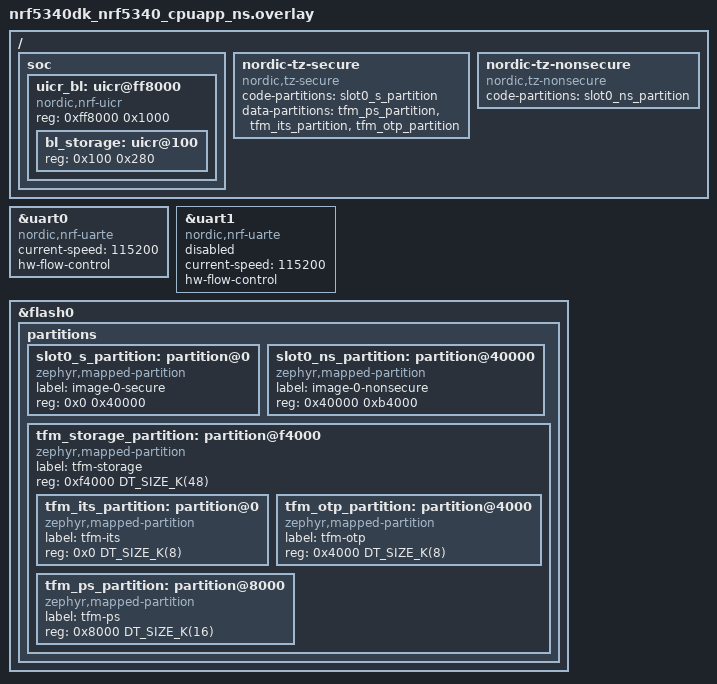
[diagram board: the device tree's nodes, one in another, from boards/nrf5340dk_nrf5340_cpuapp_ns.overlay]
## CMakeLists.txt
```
#
# Copyright (c) 2022 Nordic Semiconductor ASA
#
# SPDX-License-Identifier: LicenseRef-Nordic-5-Clause
#

cmake_minimum_required(VERSION 3.20.0)

if(${CMAKE_MAJOR_VERSION} EQUAL "3" AND ${CMAKE_MINOR_VERSION} EQUAL "25")
message(FATAL_ERROR "CMake versions 3.25.x are not compatible wth the PSA architecture tests.\n"
                    "Use an earlier (<= 3.24.x) or later (>= 3.26.x) version of CMake.")
endif()

find_package(Zephyr REQUIRED HINTS $ENV{ZEPHYR_BASE})

project(tfm_psa_test)

target_sources(app PRIVATE src/main.c)

get_target_property(TFM_BINARY_DIR           tfm TFM_BINARY_DIR)
get_target_property(TFM_NS_BIN_FILE          tfm TFM_NS_BIN_FILE)
get_target_property(TFM_NS_HEX_FILE          tfm TFM_NS_HEX_FILE)
get_target_property(TFM_NS_SIGNED_BIN_FILE   tfm TFM_NS_SIGNED_BIN_FILE)

get_target_property(TFM_TOOLCHAIN_PATH       tfm TFM_TOOLCHAIN_PATH)
get_target_property(TFM_TOOLCHAIN_PREFIX     tfm TFM_TOOLCHAIN_PREFIX)
get_target_property(TFM_TOOLCHAIN_NS_FILE    tfm TFM_TOOLCHAIN_NS_FILE)

set(TFM_TEST_REPO_PATH ${ZEPHYR_TRUSTED_FIRMWARE_M_MODULE_DIR}/../tf-m-tests)
set(TFM_PSA_ARCHTEST_REPO_PATH ${ZEPHYR_TRUSTED_FIRMWARE_M_MODULE_DIR}/../psa-arch-tests)

set(TFM_TEST_DIR         "${TFM_TEST_REPO_PATH}/tests_psa_arch/spe/partitions")
set(PSA_ARCH_TESTS_CONFIG_FILE "${TFM_TEST_REPO_PATH}/tests_psa_arch/spe/config/config_test_psa_api.cmake")

if(CONFIG_TFM_PSA_TEST_CRYPTO)
  set(TFM_PSA_TEST_SUITE CRYPTO)
elseif(CONFIG_TFM_PSA_TEST_PROTECTED_STORAGE)
  set(TFM_PSA_TEST_SUITE PROTECTED_STORAGE)
elseif(CONFIG_TFM_PSA_TEST_INTERNAL_TRUSTED_STORAGE)
  set(TFM_PSA_TEST_SUITE INTERNAL_TRUSTED_STORAGE)
elseif(CONFIG_TFM_PSA_TEST_STORAGE)
  set(TFM_PSA_TEST_SUITE STORAGE)
elseif(CONFIG_TFM_PSA_TEST_INITIAL_ATTESTATION)
  set(TFM_PSA_TEST_SUITE INITIAL_ATTESTATION)
endif()

if(NOT DEFINED TFM_PSA_TEST_SUITE)
  message(FATAL_ERROR "Please define witch test suite to run:
    CONFIG_TFM_PSA_TEST_CRYPTO
    CONFIG_TFM_PSA_TEST_PROTECTED_STORAGE
    CONFIG_TFM_PSA_TEST_INTERNAL_TRUSTED_STORAGE
    CONFIG_TFM_PSA_TEST_STORAGE
    CONFIG_TFM_PSA_TEST_INITIAL_ATTESTATION")
endif()
set(TEST_PSA_API "${TFM_PSA_TEST_SUITE}")

set_property(TARGET zephyr_property_target
             APPEND PROPERTY TFM_CMAKE_OPTIONS
             -DCONFIG_TFM_TEST_DIR=${TFM_TEST_DIR}
             -DTFM_PROFILE=profile_large
)

set_property(TARGET zephyr_property_target
             APPEND PROPERTY TFM_CMAKE_OPTIONS
             -DPSA_ARCH_TESTS_PATH=${TFM_PSA_ARCHTEST_REPO_PATH}
)

set_property(TARGET zephyr_property_target
             APPEND PROPERTY TFM_CMAKE_OPTIONS
             -DCONFIG_PSA_ARCH_TESTS_CONFIG_FILE=${PSA_ARCH_TESTS_CONFIG_FILE}
)

set_property(TARGET zephyr_property_target
             APPEND PROPERTY TFM_CMAKE_OPTIONS
             -DTEST_PSA_API=${TEST_PSA_API}
)

set(INSTALL_INTERFACE_INC_DIR ${CMAKE_BINARY_DIR}/tfm/api_ns/interface/include)

file(
  COPY
    ${ZEPHYR_OBERON_PSA_CRYPTO_MODULE_DIR}/include/psa/crypto_compat.h
    ${ZEPHYR_OBERON_PSA_CRYPTO_MODULE_DIR}/include/psa/crypto_driver_common.h
    ${ZEPHYR_OBERON_PSA_CRYPTO_MODULE_DIR}/include/psa/crypto_extra.h
    ${ZEPHYR_OBERON_PSA_CRYPTO_MODULE_DIR}/include/psa/crypto_platform.h
    ${ZEPHYR_OBERON_PSA_CRYPTO_MODULE_DIR}/include/psa/crypto_sizes.h
    ${ZEPHYR_OBERON_PSA_CRYPTO_MODULE_DIR}/include/psa/crypto_struct.h
    ${ZEPHYR_OBERON_PSA_CRYPTO_MODULE_DIR}/include/psa/crypto_types.h
    ${ZEPHYR_OBERON_PSA_CRYPTO_MODULE_DIR}/include/psa/crypto_values.h
    ${ZEPHYR_OBERON_PSA_CRYPTO_MODULE_DIR}/include/psa/crypto.h
    ${NRF_SECURITY_DIR}/include/psa/crypto_driver_contexts_key_derivation.h
    ${NRF_SECURITY_DIR}/include/psa/crypto_driver_contexts_primitives.h
    ${NRF_SECURITY_DIR}/include/psa/crypto_driver_contexts_composites.h
  DESTINATION
    ${INSTALL_INTERFACE_INC_DIR}/psa
)

# The PSA arch test non-secure app is built by the TF-M build system instead of
# Zephyr, so it takes its console UART from TF-M's NS_DRIVER_STDIO (platform
# target_cfg.h) rather than from Kconfig. NS_DRIVER_STDIO is derived from
# NRF_SECURE_UART_INSTANCE, which modules/trusted-firmware-m/CMakeLists.txt only
# passes to the secure build, so pass it to the non-secure build here as well.
foreach(uart_instance 0 1 00 20 21 22 30)
  if(CONFIG_TFM_SECURE_UART${uart_instance})
    set(tfm_ns_c_flags -DNRF_SECURE_UART_INSTANCE=${uart_instance})
  endif()
endforeach()

include(ExternalProject)

if(CONFIG_DEBUG_OPTIMIZATIONS)
  set(tfm_ns_CMAKE_BUILD_TYPE Debug)
else()
  set(tfm_ns_CMAKE_BUILD_TYPE RelWithDebInfo)
endif()

ExternalProject_Add(tfm_psa_arch_test_app
    SOURCE_DIR ${TFM_TEST_REPO_PATH}/tests_psa_arch
    BINARY_DIR ${PROJECT_BINARY_DIR}/tfm_ns
    CONFIGURE_COMMAND
        ${CMAKE_COMMAND}
                -G ${CMAKE_GENERATOR}
                -S ${TFM_TEST_REPO_PATH}/tests_psa_arch
                -B ${PROJECT_BINARY_DIR}/tfm_ns
                -DCONFIG_SPE_PATH=${TFM_BINARY_DIR}/api_ns
                -DTFM_TOOLCHAIN_FILE=cmake/${TFM_TOOLCHAIN_NS_FILE}
                -DCROSS_COMPILE=${TFM_TOOLCHAIN_PATH}/${TFM_TOOLCHAIN_PREFIX}
                -DPSA_TOOLCHAIN_FILE=${TFM_BINARY_DIR}/api_ns/cmake/${TFM_TOOLCHAIN_NS_FILE}
                -DQCBOR_PATH${QCBOR_PATH_TYPE}=${CONFIG_TFM_QCBOR_PATH}
                -DT_COSE_PATH=${CONFIG_TFM_T_COSE_PATH}
                -DCMAKE_BUILD_TYPE=${tfm_ns_CMAKE_BUILD_TYPE}
                -DTEST_PSA_API=${TEST_PSA_API}
                -DZEPHYR_NRF_MODULE_DIR=${ZEPHYR_NRF_MODULE_DIR}
                -DTFM_BOARDS_NRF_DIR=${TFM_BOARDS_NRF_DIR}
                -DNRF_CONFIG_CPU_FREQ_MHZ=${CONFIG_TFM_CPU_FREQ_MHZ}
                -DCMAKE_C_FLAGS=${tfm_ns_c_flags}
    BUILD_COMMAND ${CMAKE_COMMAND} --build .
    INSTALL_COMMAND ""
    BUILD_ALWAYS True
    USES_TERMINAL_BUILD True
    WORKING_DIRECTORY ${PROJECT_BINARY_DIR}/tfm_ns
    DEPENDS tfm
    BUILD_BYPRODUCTS
        ${TFM_NS_HEX_FILE}
        ${TFM_NS_BIN_FILE}
        ${TFM_NS_SIGNED_BIN_FILE}
)

add_dependencies(app tfm_psa_arch_test_app)
```

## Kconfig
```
#
# Copyright (c) 2026 Nordic Semiconductor ASA
#
# SPDX-License-Identifier: LicenseRef-Nordic-5-Clause
#

# Applies only to the targets with the CC3XX identity key backend.
configdefault IDENTITY_KEY_TFM
	default y

source "Kconfig.zephyr"
```

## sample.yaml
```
common:
    tags: tfm
    platform_allow: nrf5340dk_nrf5340_cpuapp_ns nrf9160dk_nrf9160_ns
    harness: console
    harness_config:
      type: multi_line
      regex:
        - "\\*\\*\\*\\*\\* PSA Architecture Test Suite - Version .* \\*\\*\\*\\*\\*"
        - "TOTAL FAILED *: 0"
sample:
  name: "TFM PSA Test"

tests:
  sample.tfm.psa_test_protected_storage:
    extra_args: "CONFIG_TFM_PSA_TEST_PROTECTED_STORAGE=y"
    timeout: 120
  sample.tfm.psa_test_internal_trusted_storage:
    extra_args: "CONFIG_TFM_PSA_TEST_INTERNAL_TRUSTED_STORAGE=y"
  sample.tfm.psa_test_storage:
    extra_args: "CONFIG_TFM_PSA_TEST_STORAGE=y"
    timeout: 130
  sample.tfm.psa_test_crypto:
    timeout: 120
    extra_args: "CONFIG_TFM_PSA_TEST_CRYPTO=y"
  sample.tfm.psa_test_initial_attestation:
    extra_args: "CONFIG_TFM_PSA_TEST_INITIAL_ATTESTATION=y"
```

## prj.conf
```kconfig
#
# Copyright (c) 2021 Nordic Semiconductor ASA
#
# SPDX-License-Identifier: LicenseRef-Nordic-5-Clause
#

CONFIG_TFM_USE_NS_APP=y

# Disable features resulting in undefined references
# when wrongfully building the Zephyr NS app.
CONFIG_PSA_CRYPTO_SYS_INIT=n
CONFIG_TFM_ALLOW_NON_SECURE_FAULT_HANDLING=n

# Needed for CRYPTO and INITIAL_ATTESTATION
CONFIG_MAIN_STACK_SIZE=4096
CONFIG_TFM_CRYPTO_ENGINE_BUF_SIZE=16536

CONFIG_TFM_ISOLATION_LEVEL=2

# Ineffective here: unsatisfied dependency HAS_HW_NRF_CC3XX on the nRF54L and nRF7120 targets, which
# use CRACEN, so IDENTITY_KEY_TFM stays n there; moved to Kconfig as a default.
# CONFIG_IDENTITY_KEY_TFM=y

CONFIG_PSA_CRYPTO=y

# RNG
CONFIG_PSA_WANT_GENERATE_RANDOM=y

# Keys
CONFIG_PSA_WANT_KEY_TYPE_AES=y
CONFIG_PSA_WANT_KEY_TYPE_CHACHA20=y
CONFIG_PSA_WANT_KEY_TYPE_ECC_KEY_PAIR_IMPORT=y
CONFIG_PSA_WANT_KEY_TYPE_ECC_KEY_PAIR_EXPORT=y
CONFIG_PSA_WANT_KEY_TYPE_ECC_KEY_PAIR_DERIVE=y
CONFIG_PSA_WANT_KEY_TYPE_ECC_KEY_PAIR_GENERATE=y
CONFIG_PSA_WANT_KEY_TYPE_RSA_KEY_PAIR_IMPORT=y
CONFIG_PSA_WANT_KEY_TYPE_RSA_KEY_PAIR_EXPORT=y
CONFIG_PSA_WANT_KEY_TYPE_RSA_KEY_PAIR_GENERATE=y
CONFIG_PSA_WANT_KEY_TYPE_RSA_KEY_PAIR_DERIVE=y


# Ciphers
CONFIG_PSA_WANT_ALG_ECB_NO_PADDING=y
CONFIG_PSA_WANT_ALG_CBC_NO_PADDING=y
CONFIG_PSA_WANT_ALG_CBC_PKCS7=y
CONFIG_PSA_WANT_ALG_CTR=y
CONFIG_PSA_WANT_ALG_CCM_STAR_NO_TAG=y
CONFIG_PSA_WANT_ALG_STREAM_CIPHER=y

# Key derivation functions
CONFIG_PSA_WANT_ALG_HKDF=y
CONFIG_PSA_WANT_ALG_TLS12_PRF=y
CONFIG_PSA_WANT_ALG_TLS12_PSK_TO_MS=y

# MAC
CONFIG_PSA_WANT_ALG_CMAC=y
CONFIG_PSA_WANT_ALG_HMAC=y

# AEAD
CONFIG_PSA_WANT_ALG_CCM=y
CONFIG_PSA_WANT_ALG_GCM=y
CONFIG_PSA_WANT_ALG_CHACHA20_POLY1305=y

# ECC
CONFIG_PSA_WANT_ALG_ECDH=y
CONFIG_PSA_WANT_ALG_ECDSA=y
CONFIG_PSA_WANT_ALG_DETERMINISTIC_ECDSA=y

# ECC curves
CONFIG_PSA_WANT_ECC_MONTGOMERY_255=y
CONFIG_PSA_WANT_ECC_TWISTED_EDWARDS_255=y
CONFIG_PSA_WANT_ECC_SECP_R1_224=y
CONFIG_PSA_WANT_ECC_SECP_R1_256=y
CONFIG_PSA_WANT_ECC_SECP_R1_384=y

# RSA
CONFIG_PSA_WANT_ALG_RSA_OAEP=y
CONFIG_PSA_WANT_ALG_RSA_PKCS1V15_CRYPT=y
CONFIG_PSA_WANT_ALG_RSA_PKCS1V15_SIGN=y
CONFIG_PSA_WANT_ALG_RSA_PSS=y

# RSA requires at least one key size to be enabled
CONFIG_PSA_WANT_RSA_KEY_SIZE_1024=y

# HASH
CONFIG_PSA_WANT_ALG_SHA_1=n # This is used to test not supported return code
CONFIG_PSA_WANT_ALG_SHA_224=y
CONFIG_PSA_WANT_ALG_SHA_256=y
CONFIG_PSA_WANT_ALG_SHA_384=y
CONFIG_PSA_WANT_ALG_SHA_512=y
```

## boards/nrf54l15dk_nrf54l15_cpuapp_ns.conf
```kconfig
# enable/Disable features that 54l supports/does not support

CONFIG_TFM_PARTITION_PROTECTED_STORAGE=n


CONFIG_TFM_PSA_TEST_CRYPTO=n
CONFIG_TFM_PSA_TEST_PROTECTED_STORAGE=n
CONFIG_TFM_PSA_TEST_STORAGE=n
CONFIG_TFM_PSA_TEST_INITIAL_ATTESTATION=n

CONFIG_TFM_PSA_TEST_INTERNAL_TRUSTED_STORAGE=y
```

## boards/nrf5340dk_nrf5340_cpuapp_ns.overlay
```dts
/*
 * Copyright (c) 2024 Nordic Semiconductor ASA
 *
 * SPDX-License-Identifier: LicenseRef-Nordic-5-Clause
 */
&uart0 {
	compatible = "nordic,nrf-uarte";
	current-speed = <115200>;
	status = "okay";
	hw-flow-control;
};

&uart1 {
	compatible = "nordic,nrf-uarte";
	current-speed = <115200>;
	/* Set to disabled in application, since TF-M will be using it. */
	status = "disabled";
	hw-flow-control;
};

/delete-node/ &boot_partition;
/delete-node/ &slot0_partition;
/delete-node/ &slot1_partition;
/delete-node/ &tfm_ps_partition;
/delete-node/ &tfm_its_partition;
/delete-node/ &tfm_otp_partition;
/delete-node/ &storage_partition;

/* Resolve bl_storage in the forwarded TF-M secure image. */
/ {
	soc {
		uicr_bl: uicr@ff8000 {
			compatible = "nordic,nrf-uicr";
			reg = <0xff8000 0x1000>;
			ranges = <0x0 0xff8000 0x1000>;
			#address-cells = <1>;
			#size-cells = <1>;

			bl_storage: uicr@100 {
				reg = <0x100 0x280>;
			};
		};
	};
};

&flash0 {
	partitions {
		slot0_s_partition: partition@0 {
			compatible = "zephyr,mapped-partition";
			label = "image-0-secure";
			reg = <0x0 0x40000>;
		};

		slot0_ns_partition: partition@40000 {
			compatible = "zephyr,mapped-partition";
			label = "image-0-nonsecure";
			reg = <0x40000 0xb4000>;
		};

		tfm_storage_partition: partition@f4000 {
			compatible = "zephyr,mapped-partition";
			label = "tfm-storage";
			reg = <0xf4000 DT_SIZE_K(48)>;
			ranges = <0x0 0xf4000 DT_SIZE_K(48)>;
			#address-cells = <1>;
			#size-cells = <1>;

			tfm_its_partition: partition@0 {
				compatible = "zephyr,mapped-partition";
				label = "tfm-its";
				reg = <0x0 DT_SIZE_K(8)>;
			};

			tfm_otp_partition: partition@4000 {
				compatible = "zephyr,mapped-partition";
				label = "tfm-otp";
				reg = <0x4000 DT_SIZE_K(8)>;
			};

			tfm_ps_partition: partition@8000 {
				compatible = "zephyr,mapped-partition";
				label = "tfm-ps";
				reg = <0x8000 DT_SIZE_K(16)>;
			};
		};
	};
};

/ {
	/delete-node/ nordic-tz-secure;
	/delete-node/ nordic-tz-nonsecure;

	nordic-tz-secure {
		compatible = "nordic,tz-secure";
		code-partitions = <&slot0_s_partition>;
		data-partitions = <&tfm_ps_partition>,
				  <&tfm_its_partition>,
				  <&tfm_otp_partition>;
	};

	nordic-tz-nonsecure {
		compatible = "nordic,tz-nonsecure";
		code-partitions = <&slot0_ns_partition>;
	};
};
```

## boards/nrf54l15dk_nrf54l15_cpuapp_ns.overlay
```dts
/*
 * Copyright (c) 2026 Nordic Semiconductor ASA
 *
 * SPDX-License-Identifier: LicenseRef-Nordic-5-Clause
 */

/* TF-M's bl_storage.c reads the provisioning data address from the
 * `bl_storage` DT nodelabel when neither Partition Manager nor a B0
 * forwarded TFM_BL_STORAGE_ADDR provides it. The nRF54L secure-side DTS
 * defines this node in nrf54l15_cpuapp_partition.dtsi, but the non-secure
 * DTS removes UICR (USE_NON_SECURE_ADDRESS_MAP), so expose it here. The NS
 * image never accesses UICR; this node is only used at compile time by the
 * TF-M secure build.
 */
/ {
	soc {
		#address-cells = <1>;
		#size-cells = <1>;

		uicr_tfm: uicr@ffd000 {
			compatible = "nordic,nrf-uicr";
			reg = <0xffd000 0x1000>;
			ranges = <0x0 0xffd000 0x1000>;
			#address-cells = <1>;
			#size-cells = <1>;

			bl_storage: uicr@500 {
				reg = <0x500 0x460>;
			};
		};
	};
};
```

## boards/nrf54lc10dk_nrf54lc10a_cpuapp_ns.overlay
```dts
/*
 * Copyright (c) 2026 Nordic Semiconductor ASA
 *
 * SPDX-License-Identifier: LicenseRef-Nordic-5-Clause
 */

/* TF-M's bl_storage.c reads the provisioning data address from the
 * `bl_storage` DT nodelabel when neither Partition Manager nor a B0
 * forwarded TFM_BL_STORAGE_ADDR provides it. The nRF54L secure-side DTS
 * defines this node in nrf54lc10a_cpuapp_partition.dtsi, but the non-secure
 * DTS removes UICR (USE_NON_SECURE_ADDRESS_MAP), so expose it here. The NS
 * image never accesses UICR; this node is only used at compile time by the
 * TF-M secure build.
 */
/ {
	soc {
		#address-cells = <1>;
		#size-cells = <1>;

		uicr_tfm: uicr@ffd000 {
			compatible = "nordic,nrf-uicr";
			reg = <0xffd000 0x1000>;
			ranges = <0x0 0xffd000 0x1000>;
			#address-cells = <1>;
			#size-cells = <1>;

			bl_storage: uicr@500 {
				reg = <0x500 0x460>;
			};
		};
	};
};
```

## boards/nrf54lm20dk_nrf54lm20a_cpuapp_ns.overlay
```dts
/*
 * Copyright (c) 2026 Nordic Semiconductor ASA
 *
 * SPDX-License-Identifier: LicenseRef-Nordic-5-Clause
 */

/* TF-M's bl_storage.c reads the provisioning data address from the
 * `bl_storage` DT nodelabel when neither Partition Manager nor a B0
 * forwarded TFM_BL_STORAGE_ADDR provides it. The nRF54L secure-side DTS
 * defines this node in nrf54lm20a_cpuapp_partition.dtsi, but the non-secure
 * DTS removes UICR (USE_NON_SECURE_ADDRESS_MAP), so expose it here. The NS
 * image never accesses UICR; this node is only used at compile time by the
 * TF-M secure build.
 */
/ {
	soc {
		#address-cells = <1>;
		#size-cells = <1>;

		uicr_tfm: uicr@ffd000 {
			compatible = "nordic,nrf-uicr";
			reg = <0xffd000 0x1000>;
			ranges = <0x0 0xffd000 0x1000>;
			#address-cells = <1>;
			#size-cells = <1>;

			bl_storage: uicr@500 {
				reg = <0x500 0x460>;
			};
		};
	};
};
```

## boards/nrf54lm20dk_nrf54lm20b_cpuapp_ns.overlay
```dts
/*
 * Copyright (c) 2026 Nordic Semiconductor ASA
 *
 * SPDX-License-Identifier: LicenseRef-Nordic-5-Clause
 */

/* TF-M's bl_storage.c reads the provisioning data address from the
 * `bl_storage` DT nodelabel when neither Partition Manager nor a B0
 * forwarded TFM_BL_STORAGE_ADDR provides it. The nRF54L secure-side DTS
 * defines this node in nrf54lm20b_cpuapp_partition.dtsi, but the non-secure
 * DTS removes UICR (USE_NON_SECURE_ADDRESS_MAP), so expose it here. The NS
 * image never accesses UICR; this node is only used at compile time by the
 * TF-M secure build.
 */
/ {
	soc {
		#address-cells = <1>;
		#size-cells = <1>;

		uicr_tfm: uicr@ffd000 {
			compatible = "nordic,nrf-uicr";
			reg = <0xffd000 0x1000>;
			ranges = <0x0 0xffd000 0x1000>;
			#address-cells = <1>;
			#size-cells = <1>;

			bl_storage: uicr@500 {
				reg = <0x500 0x460>;
			};
		};
	};
};
```

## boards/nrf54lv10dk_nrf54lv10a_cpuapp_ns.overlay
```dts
/*
 * Copyright (c) 2026 Nordic Semiconductor ASA
 *
 * SPDX-License-Identifier: LicenseRef-Nordic-5-Clause
 */

/* TF-M's bl_storage.c reads the provisioning data address from the
 * `bl_storage` DT nodelabel when neither Partition Manager nor a B0
 * forwarded TFM_BL_STORAGE_ADDR provides it. The nRF54L secure-side DTS
 * defines this node in nrf54lv10a_cpuapp_partition.dtsi, but the non-secure
 * DTS removes UICR (USE_NON_SECURE_ADDRESS_MAP), so expose it here. The NS
 * image never accesses UICR; this node is only used at compile time by the
 * TF-M secure build.
 */
/ {
	soc {
		#address-cells = <1>;
		#size-cells = <1>;

		uicr_tfm: uicr@ffd000 {
			compatible = "nordic,nrf-uicr";
			reg = <0xffd000 0x1000>;
			ranges = <0x0 0xffd000 0x1000>;
			#address-cells = <1>;
			#size-cells = <1>;

			bl_storage: uicr@500 {
				reg = <0x500 0x460>;
			};
		};
	};
};
```

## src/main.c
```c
/*
 * Copyright (c) 2022-2024 Nordic Semiconductor ASA.
 *
 * SPDX-License-Identifier: LicenseRef-Nordic-5-Clause
 */

#include <zephyr/kernel.h>

#ifdef CONFIG_TFM_PSA_TEST_NONE
#error "No PSA test suite set. See "Building and Running" in README."
#endif

int main(void)
{
	printk("Should not be printed, expected TF-M's NS application to be run instead.\n");
	k_panic();

	return 0;		/* unreachable */
}
```
